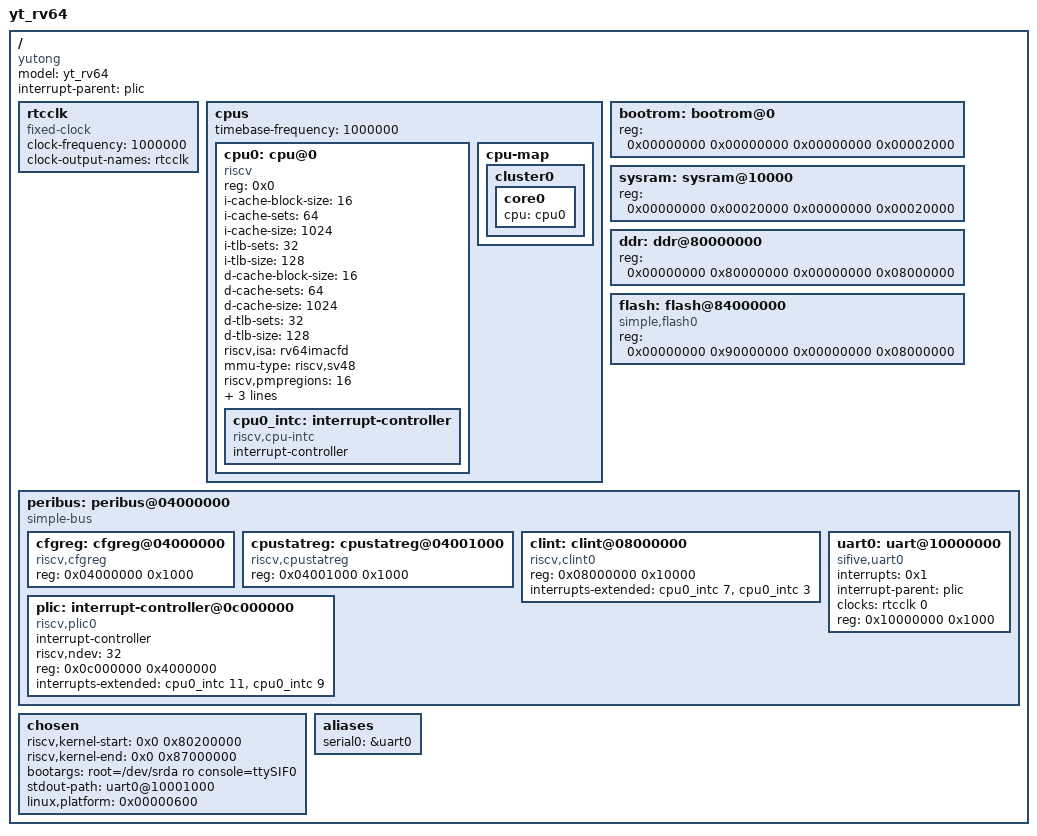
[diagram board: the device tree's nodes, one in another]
/dts-v1/;

/ {
    model = "yt_rv64";
    compatible = "yutong", "yt_rv64";
    #address-cells = <2>;
    #size-cells = <2>;
    interrupt-parent = <&plic>;

    rtcclk: rtcclk {
        compatible = "fixed-clock";
        #clock-cells = <1>;
        clock-frequency = <1000000>;
        clock-output-names = "rtcclk";
    };

    cpus {
        linux,phandle = <1>;
        #address-cells = <1>;
        #size-cells = <0>;
        timebase-frequency = <1000000>;
        cpu0: cpu@0 {
            device_type = "cpu";
            reg = <0x0>;
            status = "okay";
            compatible = "riscv";
            i-cache-block-size = <16>;
            i-cache-sets = <64>;
            i-cache-size = <1024>;
            i-tlb-sets = <32>;
            i-tlb-size = <128>;
            d-cache-block-size = <16>;
            d-cache-sets = <64>;
            d-cache-size = <1024>;
            d-tlb-sets = <32>;
            d-tlb-size = <128>;
            riscv,isa = "rv64imacfd";
            mmu-type = "riscv,sv48";
            riscv,pmpregions = <16>;
            riscv,pmpgranularity = <4>;
            clock-frequency = <33000000>;
            linux,boot-cpu;
            cpu0_intc: interrupt-controller {
                #interrupt-cells = <1>;
                interrupt-controller;
                compatible = "riscv,cpu-intc";
            };
        };
        
        cpu-map {
            cluster0 {
                core0 {
                    cpu = <&cpu0>;
                };
            };
        };
    };

    bootrom: bootrom@0 {
        device_type = "bootrom";
        reg = <0x00000000 0x00000000 0x00000000 0x00002000>;
    };

    sysram: sysram@10000 {
        device_type = "memory";
        reg = <0x00000000 0x00020000 0x00000000 0x00020000>;
    };

    ddr: ddr@80000000 {
        device_type = "memory";
        reg = <0x00000000 0x80000000 0x00000000 0x08000000>;
    };
         
    flash: flash@84000000 {
        compatible = "simple,flash0";
        reg = <0x00000000 0x90000000 0x00000000 0x08000000>;
    };

    peribus: peribus@04000000 {
        compatible = "simple-bus";
        #address-cells = <1>;
        #size-cells = <1>;
        ranges;
        
        cfgreg: cfgreg@04000000 {
            compatible = "riscv,cfgreg";
            reg = <0x04000000 0x1000>;
        };

        cpustatreg: cpustatreg@04001000 {
            compatible = "riscv,cpustatreg";
            reg = <0x04001000 0x1000>;
        };

        clint: clint@08000000 {
            compatible = "riscv,clint0";
            reg = <0x08000000 0x10000>;
            interrupts-extended = <&cpu0_intc 7>, <&cpu0_intc 3>;
        };

        plic: interrupt-controller@0c000000{
            #interrupt-cells = <1>;
            interrupt-controller;
            compatible = "riscv,plic0";
            riscv,ndev = <32>;
            reg = <0x0c000000 0x4000000>;
            interrupts-extended = <&cpu0_intc 11>, <&cpu0_intc 9>;
        };

        uart0: uart@10000000 {
            interrupts = <0x1>;
            interrupt-parent = <&plic>;
            compatible = "sifive,uart0";
            clocks = <&rtcclk 0>;
            reg = <0x10000000 0x1000>;
        };
/*
        spi0: spi@10001000 {
            interrupts = <0x2>;
            interrupt-parent = <&plic>;
            compatible = "riscv,spi0";
            reg = <0x10001000 0x1000>;
            #address-cells = <1>;
            #size-cells = <0>;
            status = "okay";

            spidev@0 {
                compatible = "rohm,dh2228fv";
                reg = <0x0>;
                spi-max-frequency = <1000000>;
                voltage-ranges = <0xce4 0xce4>;
                disable-wp;
            };

            mmc@1 {
                compatible = "mmc-spi-slot";
                reg = <0x1>;
                spi-max-frequency = <1000000>;
                voltage-ranges = <0xce4 0xce4>;
                disable-wp;
            };
        };
        */
    };

    chosen {
        riscv,kernel-start = <0x0 0x80200000>;
        riscv,kernel-end   = <0x0 0x87000000>;
        bootargs = "root=/dev/srda ro console=ttySIF0";
        stdout-path = "uart0@10001000";
        linux,platform = <0x00000600>;
    };

    aliases {
        serial0 = &uart0;
    };
};
